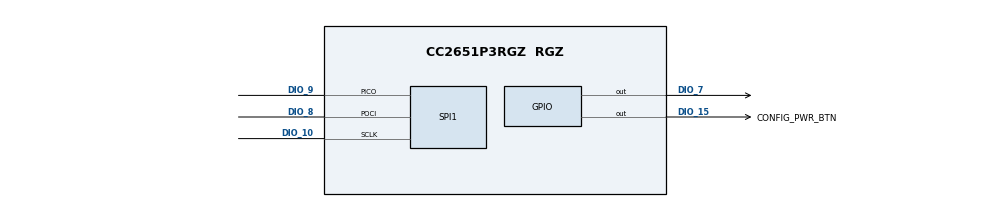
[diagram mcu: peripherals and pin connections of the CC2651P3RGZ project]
/**
 * @cliArgs --device "CC2651P3RGZ" --package "RGZ" --part "Default" --rtos "tirtos7" --product "simplelink_cc13xx_cc26xx_sdk@7.41.00.17"
 * @versions {"tool":"1.18.1+3343"}
 */

/**
 * Import the modules used in this configuration.
 */
const custom      = scripting.addModule("/ti/devices/radioconfig/custom");
const Board       = scripting.addModule("/ti/drivers/Board");
const GPIO        = scripting.addModule("/ti/drivers/GPIO");
const GPIO1       = GPIO.addInstance();
const GPIO2       = GPIO.addInstance();
const Power       = scripting.addModule("/ti/drivers/Power");
const SPI         = scripting.addModule("/ti/drivers/SPI", {}, false);
const SPI1        = SPI.addInstance();
const Temperature = scripting.addModule("/ti/drivers/Temperature");
const Settings    = scripting.addModule("/ti/posix/tirtos/Settings");
const BIOS        = scripting.addModule("/ti/sysbios/BIOS");
const Event       = scripting.addModule("/ti/sysbios/knl/Event");
const Idle        = scripting.addModule("/ti/sysbios/knl/Idle", {}, false);
const Idle2       = Idle.addInstance();
const Mailbox     = scripting.addModule("/ti/sysbios/knl/Mailbox");
const Error       = scripting.addModule("/ti/sysbios/runtime/Error");
const SysCallback = scripting.addModule("/ti/sysbios/runtime/SysCallback");
const Timestamp   = scripting.addModule("/ti/sysbios/runtime/Timestamp");

/**
 * Write custom configuration values to the imported modules.
 */
custom.prop2                                        = ["custom2400"];
custom.radioConfigcustom2400.$name                  = "ti_devices_radioconfig_settings_prop0";
custom.radioConfigcustom2400.codeExportConfig.$name = "ti_devices_radioconfig_code_export_param0";

Board.generateInitializationFunctions = false;

GPIO1.mode            = "Output";
GPIO1.$name           = "CONFIG_GPIO_GREEN_LED";
GPIO1.gpioPin.$assign = "DIO_7";

GPIO2.interruptTrigger = "Falling Edge";
GPIO2.pull             = "Pull Up";
GPIO2.$name            = "CONFIG_PWR_BTN";
GPIO2.gpioPin.$assign  = "DIO_15";

Power.policyFunction = "PowerCC26XX_doWFI";

const CCFG              = scripting.addModule("/ti/devices/CCFG", {}, false);
CCFG.ccfgTemplate.$name = "ti_devices_CCFG_CCFGCC26XXTemplate0";

SPI1.$name                    = "CONFIG_AFE_SPI";
SPI1.spi.$assign              = "SSI0";
SPI1.spi.sclkPin.$assign      = "DIO_10";
SPI1.spi.pociPin.$assign      = "DIO_8";
SPI1.spi.picoPin.$assign      = "DIO_9";
SPI1.spi.dmaRxChannel.$assign = "DMA_CH3";
SPI1.spi.dmaTxChannel.$assign = "DMA_CH4";

BIOS.assertsEnabled = false;
BIOS.heapBaseAddr   = "__primary_heap_start__";
BIOS.heapEndAddr    = "__primary_heap_end__";

const Clock      = scripting.addModule("/ti/sysbios/knl/Clock", {}, false);
Clock.tickPeriod = 10;

const Timer       = scripting.addModule("/ti/sysbios/family/arm/cc26xx/Timer", {}, false);
Timer.rtc.$assign = "RTC0";

Idle2.$name   = "powerIdle";
Idle2.idleFxn = "Power_idleFunc";

const Semaphore          = scripting.addModule("/ti/sysbios/knl/Semaphore", {}, false);
Semaphore.supportsEvents = true;

const Swi         = scripting.addModule("/ti/sysbios/knl/Swi", {}, false);
Swi.numPriorities = 6;

const Task             = scripting.addModule("/ti/sysbios/knl/Task", {}, false);
Task.checkStackFlag    = false;
Task.defaultStackSize  = 512;
Task.idleTaskStackSize = 512;
Task.numPriorities     = 7;

Error.policy       = "Error_SPIN";
Error.printDetails = false;

const System           = scripting.addModule("/ti/sysbios/runtime/System", {}, false);
System.abortFxn        = "System_abortSpin";
System.exitFxn         = "System_exitSpin";
System.extendedFormats = "%f";
System.supportModule   = "SysCallback";
